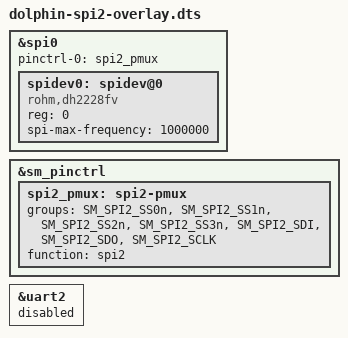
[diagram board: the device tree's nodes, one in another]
/* SPDX-License-Identifier: GPL-2.0+ */
/*
* Copyright (C) 2016~2025 Synaptics Incorporated. All rights reserved.
*
* This program is free software; you can redistribute it and/or modify
* it under the terms of the GNU General Public License version 2 or
* later as published by the Free Software Foundation.

* INFORMATION CONTAINED IN THIS DOCUMENT IS PROVIDED "AS-IS," AND
* SYNAPTICS EXPRESSLY DISCLAIMS ALL EXPRESS AND IMPLIED WARRANTIES,
* INCLUDING ANY IMPLIED WARRANTIES OF MERCHANTABILITY AND FITNESS FOR
* A PARTICULAR PURPOSE, AND ANY WARRANTIES OF NON-INFRINGEMENT OF ANY
* INTELLECTUAL PROPERTY RIGHTS. IN NO EVENT SHALL SYNAPTICS BE LIABLE
* FOR ANY DIRECT, INDIRECT, INCIDENTAL, SPECIAL, PUNITIVE, OR
* CONSEQUENTIAL DAMAGES ARISING OUT OF OR IN CONNECTION WITH THE USE
* OF THE INFORMATION CONTAINED IN THIS DOCUMENT, HOWEVER CAUSED AND
* BASED ON ANY THEORY OF LIABILITY, WHETHER IN AN ACTION OF CONTRACT,
* NEGLIGENCE OR OTHER TORTIOUS ACTION, AND EVEN IF SYNAPTICS WAS
* ADVISED OF THE POSSIBILITY OF SUCH DAMAGE. IF A TRIBUNAL OF
* COMPETENT JURISDICTION DOES NOT PERMIT THE DISCLAIMER OF DIRECT
* DAMAGES OR ANY OTHER DAMAGES, SYNAPTICS' TOTAL CUMULATIVE LIABILITY
* TO ANY PARTY SHALL NOT EXCEED ONE HUNDRED U.S. DOLLARS.
*/

// enable SPI2 located on the 40 pin connector

/dts-v1/;
/plugin/;

/ {
        fragment@0 {
                target = <&spi0>;
                __overlay__ {
                        status = "okay";
                        pinctrl-0    = <&spi2_pmux>;
                        pinctrl-names = "default";

                        spidev0: spidev@0 {
                                compatible       = "rohm,dh2228fv", "spidev";
                                reg              = <0>;          /* CS0 */
                                spi-max-frequency = <1000000>;   /* 1 MHz */
                        };
                };
        };

        fragment@1 {
                target = <&sm_pinctrl>;
                __overlay__ {
                        spi2_pmux: spi2-pmux {
                                groups = "SM_SPI2_SS0n", "SM_SPI2_SS1n",
                                         "SM_SPI2_SS2n", "SM_SPI2_SS3n",
                                         "SM_SPI2_SDI",  "SM_SPI2_SDO",
                                         "SM_SPI2_SCLK";
                                function = "spi2";
                        };
                };
        };

        fragment@2 {
                target = <&uart2>;
                __overlay__ {
                        status = "disabled";
                };
        };
};
